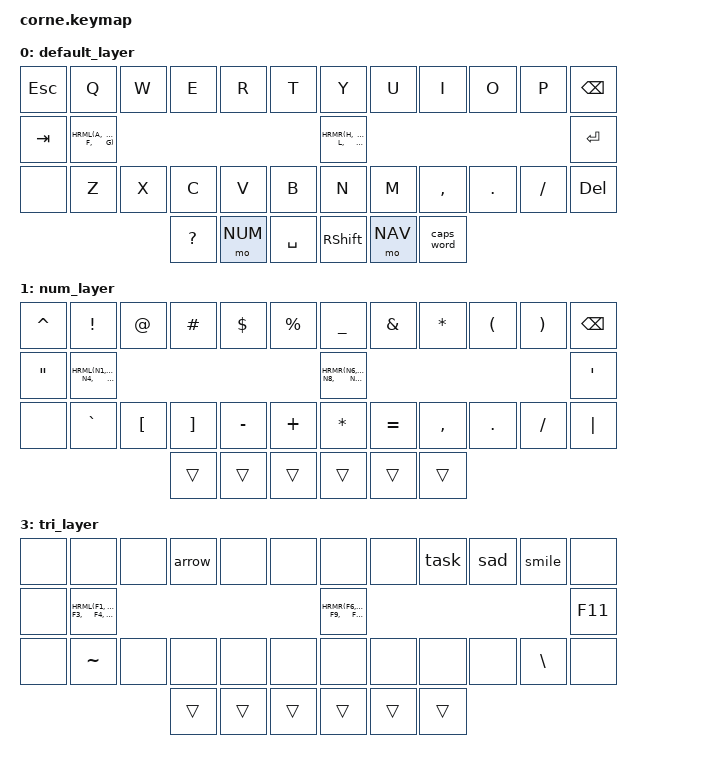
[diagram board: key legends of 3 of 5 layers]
/*
 * Copyright (c) 2020 The ZMK Contributors
 *
 * SPDX-License-Identifier: MIT
 */

#include <behaviors.dtsi>
#include <dt-bindings/zmk/keys.h>
#include <dt-bindings/zmk/bt.h>
#include <dt-bindings/zmk/outputs.h>
#include "helper.h"

#define BASE 0
#define NUM 1
#define NAV 2
#define TRI 3
#define CONF 4
#define XXX &none
#define ___ &trans
#define MEH LC(LA(LSHIFT))
#define BTC &bt BT_CLR
#define BT1 &bt BT_SEL 0
#define BT2 &bt BT_SEL 1
#define BT3 &bt BT_SEL 2
#define BT4 &bt BT_SEL 3
#define BT5 &bt BT_SEL 4

#define QUICK_TAP_MS 175
#define TAPPING_TERM_MS 300
#define REQ_PRIOR_IDLE_MS 200

// Home row mods macro
#define HRML(k1,k2,k3,k4,k5) &hml LSHIFT k1 &hml LGUI k2 &hml LALT k3 &hml LCTRL k4 &hml MEH k5
#define HRMR(k1,k2,k3,k4,k5) &hmr MEH k1 &hmr RCTRL k2  &hmr LALT k3 &hmr RGUI k4 &hmr RSHIFT k5

&caps_word {
    continue-list = <UNDERSCORE MINUS BSPC DOT>;
};

//              ┌──────┬─────┬─────┬─────┬─────┬─────┐     ┌──────┬──────┬─────┬─────┬─────┬──────┐
//              │  0   │  1  │  2  │  3  │  4  │  5  │     │  6   │  7   │  8  │  9  │ 10  │  11  │
//              ├──────┼─────┼─────┼─────┼─────┼─────┤     ├──────┼──────┼─────┼─────┼─────┼──────┤
//              │  12  │  13 │ 14  │  15 │  16 │ 17  │     │  18  │  19  │  20 │  21 │ 22  │  23  │
//              ├──────┼─────┼─────┼─────┼─────┼─────┤     ├──────┼──────┼─────┼─────┼─────┼──────┤
//              │  24  │  25 │  26 │  27 │  28 │  29 │     │  30  │  31  │  32 │  33 │ 34  │  35  │
//              └──────┴─────┴─────┼─────┼─────┼─────┤     ├──────┼──────┼─────┼─────┴─────┴──────┘
//                                 │  36 │  37 │  38 │     │  39  │  40  │  41 │
//                                 └─────┴─────┴─────┘     └──────┴──────┴─────┘
#define KEYS_L 0 1 2 3 4 5 12 13 14 15 16 17 24 25 26 27 28 29     // left-hand keys
#define KEYS_R 6 7 8 9 10 11 18 19 20 21 22 23 30 31 32 33 34 35   // right-hand keys
#define THUMBS 36 37 38 39 40 41                                   // thumb keys

ZMK_BEHAVIOR(hml, hold_tap,  // left-hand HRMs
    flavor = "balanced";
    tapping-term-ms = <TAPPING_TERM_MS>;
    quick-tap-ms = <QUICK_TAP_MS>;
    require-prior-idle-ms = <REQ_PRIOR_IDLE_MS>;
    hold-trigger-on-release;
    bindings = <&kp>, <&kp>;
    hold-trigger-key-positions = <KEYS_R THUMBS>;
)

ZMK_BEHAVIOR(hmr, hold_tap,  // right-hand HRMs
    flavor = "balanced";
    tapping-term-ms = <TAPPING_TERM_MS>;
    quick-tap-ms = <QUICK_TAP_MS>;
    require-prior-idle-ms = <REQ_PRIOR_IDLE_MS>;
    hold-trigger-on-release;
    bindings = <&kp>, <&kp>;
    hold-trigger-key-positions = <KEYS_L THUMBS>;
)

#undef COMBO_TERM
#define COMBO_TERM 40  // timeout of 40ms (default is 30ms if omitted)
ZMK_COMBO(lockscr,      &kp LG(L),      0 1 2,    BASE)   // lock screen by pressing ESC Q W
ZMK_COMBO(conflayer,    &to CONF,       0 11,     BASE)   // ESC BSPC
ZMK_COMBO(capsword,     &caps_word,     13 22,    BASE)   // A:
ZMK_COMBO(ctrlspce,     &kp LC(SPACE),  16 19,    BASE)   // FJ

ZMK_BEHAVIOR(smile, macro,
    wait-ms = <100>;
    tap-ms = <5>;
    bindings = <&macro_tap &kp COLON &kp MINUS &kp RPAR>;
)
ZMK_BEHAVIOR(sad, macro,
    wait-ms = <100>;
    tap-ms = <5>;
    bindings = <&macro_tap &kp COLON &kp MINUS &kp LPAR>;
)
ZMK_BEHAVIOR(arrow, macro,
    wait-ms = <100>;
    tap-ms = <5>;
    bindings = <&macro_tap &kp MINUS &kp GT>;
)
ZMK_BEHAVIOR(task, macro,
    wait-ms = <100>;
    tap-ms = <5>;
    bindings = <&macro_tap &kp MINUS &kp SPACE &kp LBKT &kp SPACE &kp RBKT &kp SPACE>;
)
ZMK_CONDITIONAL_LAYER (1 2, 3)

//              ┌──────┬─────┬─────┬─────┬─────┬─────┐     ┌──────┬──────┬─────┬─────┬─────┬──────┐
//              │ ESC  │  Q  │  W  │  E  │  R  │  T  │     │  Y   │  U   │  I  │  O  │  P  │  BSP │
//              ├──────┼─────┼─────┼─────┼─────┼─────┤     ├──────┼──────┼─────┼─────┼─────┼──────┤
//              │  TAB │  A  │  S  │  D  │  F  │  G  │     │  H   │  J   │  K  │  L  │ ;   │  ENT │
//              ├──────┼─────┼─────┼─────┼─────┼─────┤     ├──────┼──────┼─────┼─────┼─────┼──────┤
//              │      │  Z  │  X  │  C  │  V  │  B  │     │  N   │  M   │  ,  │  .  │ /   │  DEL │
//              └──────┴─────┴─────┼─────┼─────┼─────┤     ├──────┼──────┼─────┼─────┴─────┴──────┘
//                                 │  ?  │ NUM │ SPC │     │ SHFT │ NAV  │CAPW │
//                                 └─────┴─────┴─────┘     └──────┴──────┴─────┘
ZMK_LAYER(default_layer,
                &kp ESC    &kp Q    &kp W  &kp E     &kp R    &kp T              &kp Y       &kp U    &kp I      &kp O    &kp P     &kp BSPC
                &kp TAB    HRML(A,  S,     D,        F,       G)                 HRMR(H,     J,       K,         L,       SEMI)     &kp ENTER
                XXX        &kp Z    &kp X  &kp C     &kp V    &kp B              &kp N       &kp M    &kp COMMA  &kp DOT  &kp FSLH  &kp DEL
                                           &kp QMARK &mo NUM  &kp SPACE          &kp RSHIFT  &mo NAV  &caps_word
)

//              ┌──────┬─────┬─────┬─────┬─────┬─────┐     ┌──────┬──────┬─────┬─────┬─────┬──────┐
//              │   ^  │  !  │  @  │  #  │  $  │  %  │     │  _   │  &   │  *  │  (  │  )  │ BSP  │
//              ├──────┼─────┼─────┼─────┼─────┼─────┤     ├──────┼──────┼─────┼─────┼─────┼──────┤
//              │   "  │  1  │  2  │  3  │  4  │  5  │     │  6   │  7   │  8  │  9  │  0  │  '   │
//              ├──────┼─────┼─────┼─────┼─────┼─────┤     ├──────┼──────┼─────┼─────┼─────┼──────┤
//              │      │  `  │  [  │  ]  │  -  │  +  │     │  *   │  =   │  ,  │  .  │  /  │  |   │
//              └──────┴─────┴─────┼─────┼─────┼─────┤     ├──────┼──────┼─────┼─────┴─────┴──────┘
//                                 │  ?  │ NUM │ SPC │     │ SHFT │ NAV  │CAPW │
//                                 └─────┴─────┴─────┘     └──────┴──────┴─────┘
ZMK_LAYER(num_layer,
                &kp CARET &kp EXCL  &kp AT   &kp HASH &kp DOLLAR &kp PERCENT   &kp UNDER  &kp AMPS   &kp STAR   &kp LPAR  &kp RPAR  &kp BSPC
                &kp DQT   HRML(N1,  N2,      N3,      N4,        N5)           HRMR(N6,   N7,        N8,        N9,       N0)       &kp SQT
                XXX       &kp GRAVE &kp LBKT &kp RBKT &kp MINUS  &kp PLUS      &kp STAR   &kp EQUAL  &kp COMMA  &kp DOT   &kp FSLH  &kp PIPE
                                             ___      ___        ___           ___        ___        ___
)

//              ┌──────┬─────┬─────┬─────┬─────┬─────┐     ┌──────┬──────┬─────┬─────┬─────┬──────┐
//              │ ESC  │     │     │     │     │     │     │      │  ⌥←  │  ↑  │  ⌥→ │PGUP │ ^BSP │
//              ├──────┼─────┼─────┼─────┼─────┼─────┤     ├──────┼──────┼─────┼─────┼─────┼──────┤
//              │ TAB  │  |  │  ;  │  -  │  ,  │ ^DEL│     │      │   ←  │  ↓  │  →  │     │ ⌥ENT │
//              ├──────┼─────┼─────┼─────┼─────┼─────┤     ├──────┼──────┼─────┼─────┼─────┼──────┤
//              │      │     │     │     │     │     │     │      │ HOME │     │ END │PGDN │  DEL │
//              └──────┴─────┴─────┼─────┼─────┼─────┤     ├──────┼──────┼─────┼─────┴─────┴──────┘
//                                 │  ?  │ NUM │ SPC │     │ SHFT │  NAV │CAPW │
//                                 └─────┴─────┴─────┘     └──────┴──────┴─────┘
ZMK_LAYER(nav_layer,
   	 	        &kp ESC XXX        XXX    XXX     XXX     XXX           XXX    &kp LA(LEFT) &kp UP    &kp LA(RIGHT)  &kp PAGE_UP    &kp LC(BSPC)
   	            &kp TAB HRML(PIPE, SEMI,  MINUS,  COMMA,  LC(DEL))      XXX    &kp LEFT     &kp DOWN  &kp RIGHT      XXX            &kp LA(ENTER) 
   	            XXX     XXX        XXX    XXX     XXX     XXX           XXX    &kp HOME     XXX       &kp END        &kp PAGE_DOWN  &kp DEL
                                          ___     ___     ___           ___    ___          ___ 
)

//              ┌──────┬─────┬─────┬─────┬─────┬─────┐     ┌──────┬──────┬─────┬─────┬─────┬──────┐
//              │      │     │     │     │     │     │     │      │      │ -[] │ :-( │ :-) │      │
//              ├──────┼─────┼─────┼─────┼─────┼─────┤     ├──────┼──────┼─────┼─────┼─────┼──────┤
//              │      │  F1 │ F2  │  F3 │  F4 │ F5  │     │  F6  │  F7  │  F8 │  F9 │ F10 │ F11  │
//              ├──────┼─────┼─────┼─────┼─────┼─────┤     ├──────┼──────┼─────┼─────┼─────┼──────┤
//              │      │  ~  │     │     │     │     │     │      │      │     │     │  \  │      │
//              └──────┴─────┴─────┼─────┼─────┼─────┤     ├──────┼──────┼─────┼─────┴─────┴──────┘
//                                 │  ?  │ NUM │ SPC │     │ SHFT │ NAV  │CAPW │
//                                 └─────┴─────┴─────┘     └──────┴──────┴─────┘

ZMK_LAYER(tri_layer,
                XXX  XXX        XXX   &arrow   XXX    XXX             XXX       XXX    &task   &sad     &smile   XXX
                XXX  HRML(F1,   F2,   F3,      F4,    F5)             HRMR(F6,  F7,    F8,     F9,      F10)     &kp F11
                XXX  &kp TILDE  XXX   XXX      XXX    XXX             XXX       XXX    XXX    XXX       &kp BSLH XXX
                                      ___      ___    ___             ___       ___    ___
)

//              ┌──────┬─────┬─────┬─────┬─────┬─────┐     ┌──────┬──────┬─────┬─────┬─────┬──────┐
//              │ BASE │     │     │     │     │     │     │      │      │     │     │     │      │
//              ├──────┼─────┼─────┼─────┼─────┼─────┤     ├──────┼──────┼─────┼─────┼─────┼──────┤
//              │      │ BT1 │ BT2 │ BT3 │ BT4 │ BT5 │     │      │      │     │     │ BTC │      │
//              ├──────┼─────┼─────┼─────┼─────┼─────┤     ├──────┼──────┼─────┼─────┼─────┼──────┤
//              │      │     │     │     │     │     │     │      │      │     │     │     │      │
//              └──────┴─────┴─────┼─────┼─────┼─────┤     ├──────┼──────┼─────┼─────┴─────┴──────┘
//                                 │  ?  │  C  │  O  │     │  N   │  F   │CAPW │
//                                 └─────┴─────┴─────┘     └──────┴──────┴─────┘
ZMK_LAYER(config_layer,
                &to BASE  XXX    XXX   XXX    XXX     XXX             XXX      XXX     XXX     XXX     XXX    XXX
                XXX       BT1    BT2   BT3    BT4     BT5             XXX      XXX     XXX     XXX     BTC    XXX
                XXX       XXX    XXX   XXX    XXX     XXX             XXX      XXX     XXX     XXX     XXX    XXX
                                       ___    &kp C   &kp O           &kp N    &kp F   ___     
)
